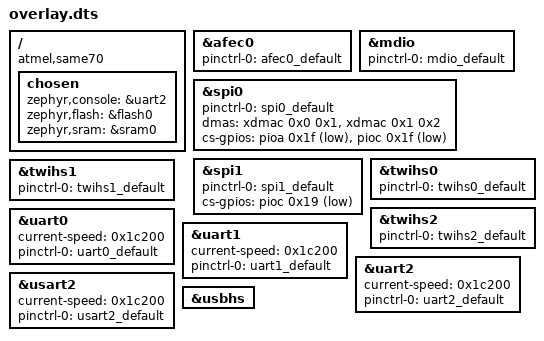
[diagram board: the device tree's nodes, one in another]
/ {
	compatible = "atmel,same70", "atmel,same70q21b", "tdk,robokit1";
	chosen {
		zephyr,console = &uart2;
		zephyr,flash = &flash0;
		zephyr,sram = &sram0;
	};
};
&afec0{
	status = "okay";
	pinctrl-0 = < &afec0_default >;
	pinctrl-names = "default";
};
&mdio{
	status = "okay";
	pinctrl-0 = < &mdio_default >;
	pinctrl-names = "default";
};
&spi0{
	status = "okay";
	pinctrl-0 = < &spi0_default >;
	pinctrl-names = "default";
	dmas = < &xdmac 0x0 0x1 >, < &xdmac 0x1 0x2 >;
	dma-names = "tx", "rx";
	cs-gpios = < &pioa 0x1f 0x1 >, < &pioc 0x1f 0x1 >;
};
&spi1{
	status = "okay";
	pinctrl-0 = < &spi1_default >;
	pinctrl-names = "default";
	cs-gpios = < &pioc 0x19 0x1 >;
};
&twihs0{
	status = "okay";
	pinctrl-0 = < &twihs0_default >;
	pinctrl-names = "default";
};
&twihs1{
	status = "okay";
	pinctrl-0 = < &twihs1_default >;
	pinctrl-names = "default";
};
&twihs2{
	status = "okay";
	pinctrl-0 = < &twihs2_default >;
	pinctrl-names = "default";
};
&uart0{
	status = "okay";
	current-speed = < 0x1c200 >;
	pinctrl-0 = < &uart0_default >;
	pinctrl-names = "default";
};
&uart1{
	status = "okay";
	current-speed = < 0x1c200 >;
	pinctrl-0 = < &uart1_default >;
	pinctrl-names = "default";
};
&uart2{
	status = "okay";
	current-speed = < 0x1c200 >;
	pinctrl-0 = < &uart2_default >;
	pinctrl-names = "default";
};
&usart2{
	status = "okay";
	current-speed = < 0x1c200 >;
	pinctrl-0 = < &usart2_default >;
	pinctrl-names = "default";
};
&usbhs{
	status = "okay";
};
